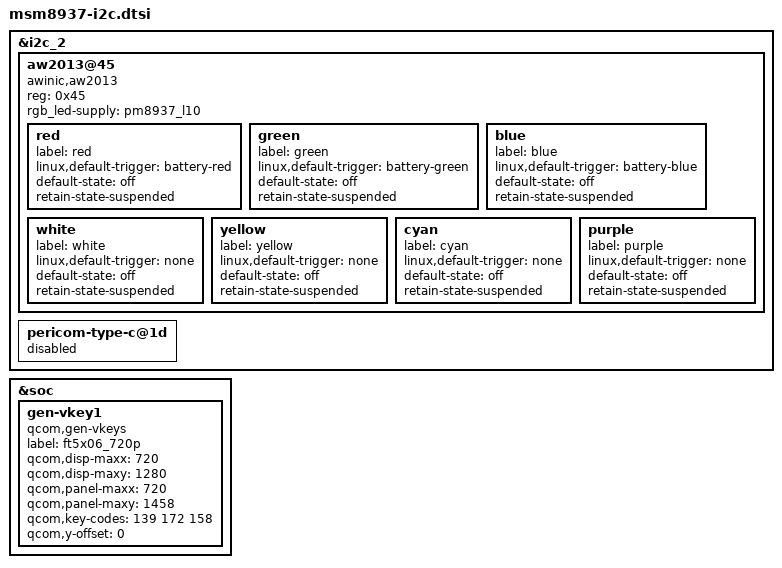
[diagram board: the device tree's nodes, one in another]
&i2c_2  {
	aw2013@45 {
		compatible = "awinic,aw2013";
		reg = <0x45>;
		rgb_led-supply = <&pm8937_l10>;

		red {
			label = "red";
			linux,default-trigger = "battery-red";
			default-state = "off";
			retain-state-suspended;
		};

		green {
			label = "green";
			linux,default-trigger = "battery-green";
			default-state = "off";
			retain-state-suspended;
		};

		blue {
			label = "blue";
			linux,default-trigger = "battery-blue";
			default-state = "off";
			retain-state-suspended;
		};

		white {
			label = "white";
			linux,default-trigger = "none";
			default-state = "off";
			retain-state-suspended;
		};

		yellow {
			label = "yellow";
			linux,default-trigger = "none";
			default-state = "off";
			retain-state-suspended;
		};

		cyan {
			label = "cyan";
			linux,default-trigger = "none";
			default-state = "off";
			retain-state-suspended;
		};

		purple {
			label = "purple";
			linux,default-trigger = "none";
			default-state = "off";
			retain-state-suspended;
		};
	};

        pericom-type-c@1d {
                status="disabled";
        };
};

&soc {
	gen-vkey1 {
		compatible = "qcom,gen-vkeys";
		label = "ft5x06_720p";
		qcom,disp-maxx = <720>;
		qcom,disp-maxy = <1280>;
		qcom,panel-maxx = <720>;
		qcom,panel-maxy = <1458>;
		qcom,key-codes = <139 172 158>;
		qcom,y-offset = <0>;
	};
};
